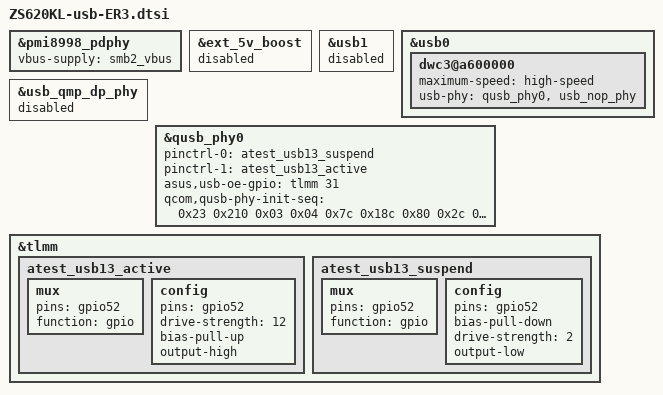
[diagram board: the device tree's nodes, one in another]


&pmi8998_pdphy {
	vbus-supply = <&smb2_vbus>;
};


&ext_5v_boost {
	status = "disabled";
};

&usb1 {
	status = "disabled";
};

&usb0 {
	dwc3@a600000 {
		maximum-speed = "high-speed";
		usb-phy = <&qusb_phy0>, <&usb_nop_phy>;
	};
};

&usb_qmp_dp_phy {
	status = "disabled";
};

&qusb_phy0 {
	pinctrl-names = "atest_usb13_suspend", "atest_usb13_active";
	pinctrl-0 = <&atest_usb13_suspend>;
	pinctrl-1 = <&atest_usb13_active>;
	asus,usb-oe-gpio = <&tlmm 31 0>;


	qcom,qusb-phy-init-seq =
	/* <value reg_offset> */
	   <0x23 0x210 /* PWR_CTRL1 */
		0x03 0x04  /* PLL_ANALOG_CONTROLS_TWO */
		0x7c 0x18c /* PLL_CLOCK_INVERTERS */
		0x80 0x2c  /* PLL_CMODE */
		0x0a 0x184 /* PLL_LOCK_DELAY */
		0x19 0xb4  /* PLL_DIGITAL_TIMERS_TWO */
		0x40 0x194 /* PLL_BIAS_CONTROL_1 */
		0x11 0x198 /* PLL_BIAS_CONTROL_2 */
		0x21 0x214 /* PWR_CTRL2 */
		0x00 0x220 /* IMP_CTRL1 */
		0x58 0x224 /* IMP_CTRL2 */
		0x37 0x240 /* TUNE1 */
		0x2B 0x244 /* TUNE2 */
		0xca 0x248 /* TUNE3 */
		0x02 0x24c /* TUNE4 */
		0x00 0x250 /* TUNE5 */
		0x00 0x23c /* CHG_CTRL2 */
		0x22 0x210>; /* PWR_CTRL1 */
};

&tlmm {
	atest_usb13_active: atest_usb13_active {
		mux {
			pins = "gpio52";
			function = "gpio";
		};
		config {
			pins = "gpio52";
			drive-strength = <12>;
			bias-pull-up;
			output-high;
		};
	};
	atest_usb13_suspend: atest_usb13_suspend {
		mux {
			pins = "gpio52";
			function = "gpio";
		};
		config {
			pins = "gpio52";
			bias-pull-down;
			drive-strength = <2>;
			output-low;
		};
	};
};
